# HC32F4A0PGTB register map
File version: 1.0
CPU: CM4 r0p1, little endian, MPU, FPU, 4 interrupt priority bits
Registers are 32-bit, read-write, reset 0x0 unless marked. A register's access mark holds for its fields unless they carry their own. Offsets are from the block's base; [hi:lo] are bit positions; {n}, {i} and the like mark numbered series; 'fields as' and 'values as' point back to an identical list.

## RMU
Base 0x4004CC00
0xF8 PRSTCR0 8-bit reset 0x40
  [5] LKUPREN
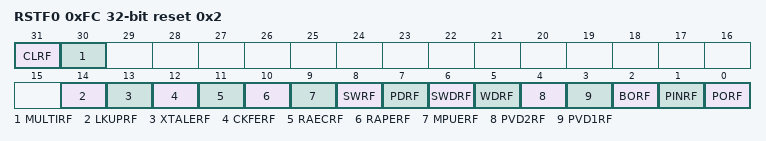
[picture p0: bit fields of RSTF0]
0xFC RSTF0 reset 0x2
  [31] CLRF, [30] MULTIRF, [14] LKUPRF, [13] XTALERF, [12] CKFERF, [11] RAECRF, [10] RAPERF, [9] MPUERF, [8] SWRF, [7] PDRF, [6] SWDRF, [5] WDRF, [4] PVD2RF, [3] PVD1RF, [2] BORF, [1] PINRF, [0] PORF

## RTC
Base 0x4004C000
0x00 CR0 8-bit
  [0] RESET
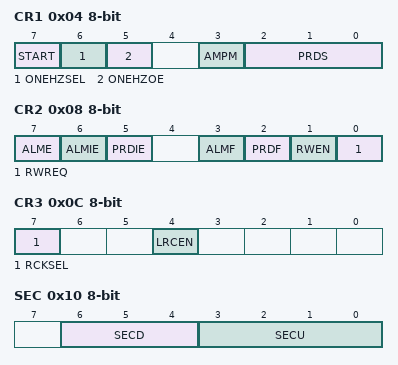
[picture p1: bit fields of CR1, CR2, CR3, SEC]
0x04 CR1 8-bit
  [7] START, [6] ONEHZSEL, [5] ONEHZOE, [3] AMPM, [2:0] PRDS
0x08 CR2 8-bit
  [7] ALME, [6] ALMIE, [5] PRDIE, [3] ALMF, [2] PRDF, [1] RWEN, [0] RWREQ
0x0C CR3 8-bit
  [7] RCKSEL, [4] LRCEN
0x10 SEC 8-bit
  [6:4] SECD, [3:0] SECU
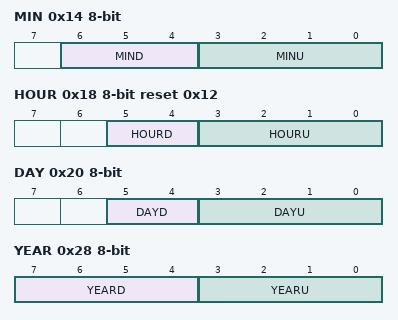
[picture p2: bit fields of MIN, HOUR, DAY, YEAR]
0x14 MIN 8-bit
  [6:4] MIND, [3:0] MINU
0x18 HOUR 8-bit reset 0x12
  [5:4] HOURD, [3:0] HOURU
0x1C WEEK 8-bit
  [2:0] WEEK
0x20 DAY 8-bit
  [5:4] DAYD, [3:0] DAYU
0x24 MON 8-bit
  [4:0] MON
0x28 YEAR 8-bit
  [7:4] YEARD, [3:0] YEARU
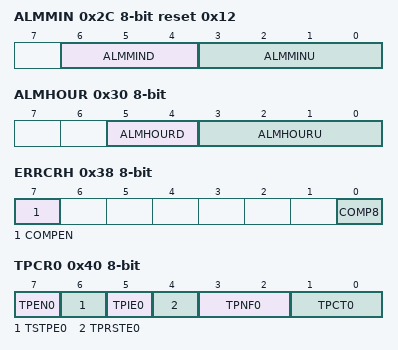
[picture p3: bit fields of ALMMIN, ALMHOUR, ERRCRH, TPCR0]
0x2C ALMMIN 8-bit reset 0x12
  [6:4] ALMMIND, [3:0] ALMMINU
0x30 ALMHOUR 8-bit
  [5:4] ALMHOURD, [3:0] ALMHOURU
0x34 ALMWEEK 8-bit
  [6:0] ALMWEEK
0x38 ERRCRH 8-bit
  [7] COMPEN, [0] COMP8
0x3C ERRCRL 8-bit
  [7:0] COMP
0x40 TPCR0 8-bit
  [7] TPEN0, [6] TSTPE0, [5] TPIE0, [4] TPRSTE0, [3:2] TPNF0, [1:0] TPCT0
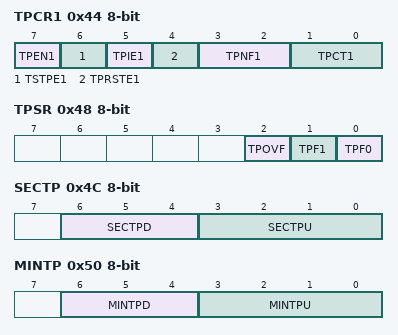
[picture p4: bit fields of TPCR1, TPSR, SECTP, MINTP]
0x44 TPCR1 8-bit
  [7] TPEN1, [6] TSTPE1, [5] TPIE1, [4] TPRSTE1, [3:2] TPNF1, [1:0] TPCT1
0x48 TPSR 8-bit
  [2] TPOVF, [1] TPF1, [0] TPF0
0x4C SECTP 8-bit
  [6:4] SECTPD, [3:0] SECTPU
0x50 MINTP 8-bit
  [6:4] MINTPD, [3:0] MINTPU
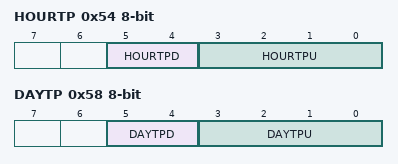
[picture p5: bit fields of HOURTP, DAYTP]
0x54 HOURTP 8-bit
  [5:4] HOURTPD, [3:0] HOURTPU
0x58 DAYTP 8-bit
  [5:4] DAYTPD, [3:0] DAYTPU
0x5C MONTP 8-bit
  [4:0] MONTP

## SDIOC1 — desc SDIOC
Base 0x40070000
Same registers: SDIOC2 0x40078400
0x04 BLKSIZE 16-bit
  [11:0] TBS
0x06 BLKCNT 16-bit
0x08 ARG0 16-bit
0x0A ARG1 16-bit
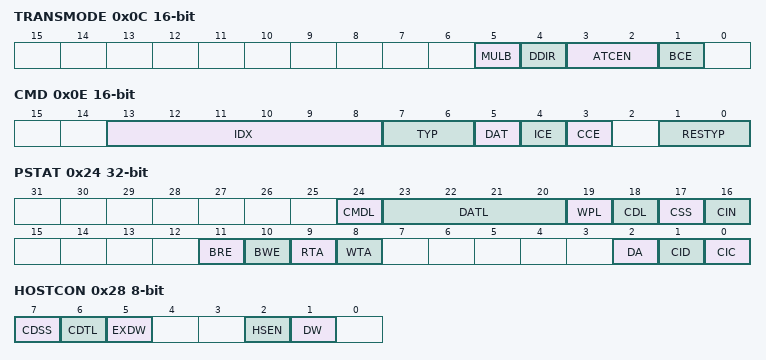
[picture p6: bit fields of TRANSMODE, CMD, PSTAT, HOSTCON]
0x0C TRANSMODE 16-bit
  [5] MULB, [4] DDIR, [3:2] ATCEN, [1] BCE
0x0E CMD 16-bit
  [13:8] IDX, [7:6] TYP, [5] DAT, [4] ICE, [3] CCE, [1:0] RESTYP
{0x10+2i} RESP{i} 16-bit ro (i=0..7)
0x20 BUF0 16-bit
0x22 BUF1 16-bit
0x24 PSTAT ro
  [24] CMDL, [23:20] DATL, [19] WPL, [18] CDL, [17] CSS, [16] CIN, [11] BRE, [10] BWE, [9] RTA, [8] WTA, [2] DA, [1] CID, [0] CIC
0x28 HOSTCON 8-bit
  [7] CDSS, [6] CDTL, [5] EXDW, [2] HSEN, [1] DW
0x29 PWRCON 8-bit
  [0] PWON
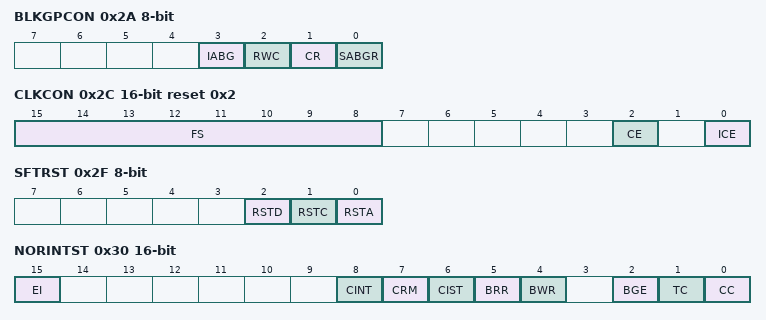
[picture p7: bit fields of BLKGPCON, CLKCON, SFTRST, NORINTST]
0x2A BLKGPCON 8-bit
  [3] IABG, [2] RWC, [1] CR, [0] SABGR
0x2C CLKCON 16-bit reset 0x2
  [15:8] FS, [2] CE, [0] ICE
0x2E TOUTCON 8-bit
  [3:0] DTO
0x2F SFTRST 8-bit
  [2] RSTD, [1] RSTC, [0] RSTA
0x30 NORINTST 16-bit
  [15] EI ro, [8] CINT ro, [7] CRM, [6] CIST, [5] BRR, [4] BWR, [2] BGE, [1] TC, [0] CC
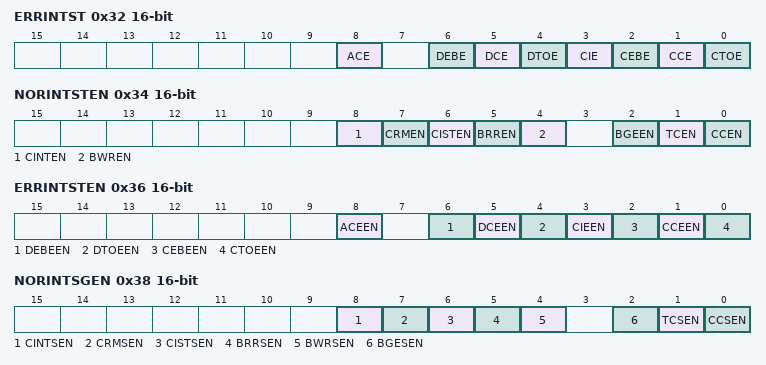
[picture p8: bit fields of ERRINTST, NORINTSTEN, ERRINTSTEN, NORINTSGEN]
0x32 ERRINTST 16-bit
  [8] ACE, [6] DEBE, [5] DCE, [4] DTOE, [3] CIE, [2] CEBE, [1] CCE, [0] CTOE
0x34 NORINTSTEN 16-bit
  [8] CINTEN, [7] CRMEN, [6] CISTEN, [5] BRREN, [4] BWREN, [2] BGEEN, [1] TCEN, [0] CCEN
0x36 ERRINTSTEN 16-bit
  [8] ACEEN, [6] DEBEEN, [5] DCEEN, [4] DTOEEN, [3] CIEEN, [2] CEBEEN, [1] CCEEN, [0] CTOEEN
0x38 NORINTSGEN 16-bit
  [8] CINTSEN, [7] CRMSEN, [6] CISTSEN, [5] BRRSEN, [4] BWRSEN, [2] BGESEN, [1] TCSEN, [0] CCSEN
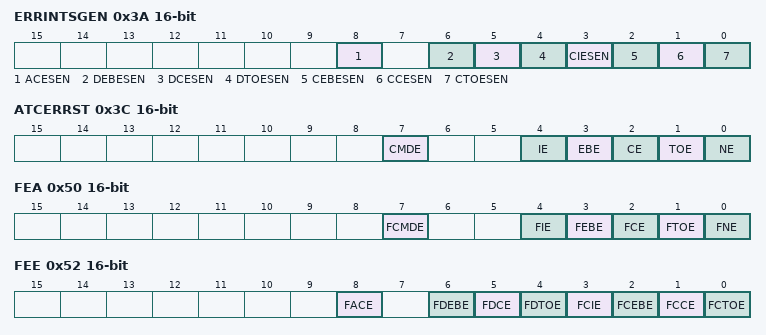
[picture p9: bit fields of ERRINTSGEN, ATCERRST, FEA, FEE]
0x3A ERRINTSGEN 16-bit
  [8] ACESEN, [6] DEBESEN, [5] DCESEN, [4] DTOESEN, [3] CIESEN, [2] CEBESEN, [1] CCESEN, [0] CTOESEN
0x3C ATCERRST 16-bit ro
  [7] CMDE, [4] IE, [3] EBE, [2] CE, [1] TOE, [0] NE
0x50 FEA 16-bit wo
  [7] FCMDE, [4] FIE, [3] FEBE, [2] FCE, [1] FTOE, [0] FNE
0x52 FEE 16-bit wo
  [8] FACE, [6] FDEBE, [5] FDCE, [4] FDTOE, [3] FCIE, [2] FCEBE, [1] FCCE, [0] FCTOE

## SMC
Base 0x88000000
0x00 STSR ro reset 0x1
  [0] STATUS
0x08 STCR0 wo
  [2] LPWIR
0x0C STCR1 wo
  [2] LPWOR
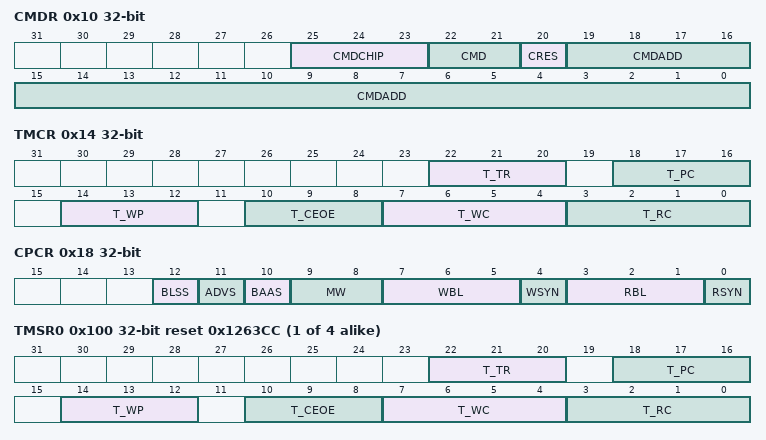
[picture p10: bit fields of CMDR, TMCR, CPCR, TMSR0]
0x10 CMDR wo
  [25:23] CMDCHIP, [22:21] CMD, [20] CRES, [19:0] CMDADD
0x14 TMCR wo
  [22:20] T_TR, [18:16] T_PC, [14:12] T_WP, [10:8] T_CEOE, [7:4] T_WC, [3:0] T_RC
0x18 CPCR wo
  [12] BLSS, [11] ADVS, [10] BAAS, [9:8] MW, [7:5] WBL, [4] WSYN, [3:1] RBL, [0] RSYN
0x20 RFTR
  [3:0] REFPRD
{0x100+0x20*i} TMSR{i} ro reset 0x1263CC (i=0..3)
  fields as TMCR
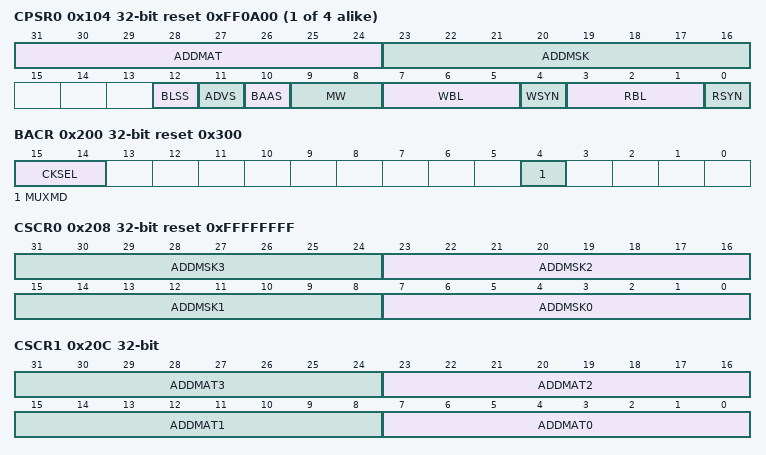
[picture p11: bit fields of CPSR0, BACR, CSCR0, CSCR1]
{0x104+0x20*i} CPSR{i} ro reset 0xFF0A00 (i=0..3)
  [31:24] ADDMAT, [23:16] ADDMSK, [12] BLSS, [11] ADVS, [10] BAAS, [9:8] MW, [7:5] WBL, [4] WSYN, [3:1] RBL, [0] RSYN
0x200 BACR reset 0x300
  [15:14] CKSEL, [4] MUXMD
0x208 CSCR0 reset 0xFFFFFFFF
  [8n+7:8n] ADDMSK{n} (n=0..3)
0x20C CSCR1
  [8n+7:8n] ADDMAT{n} (n=0..3)
